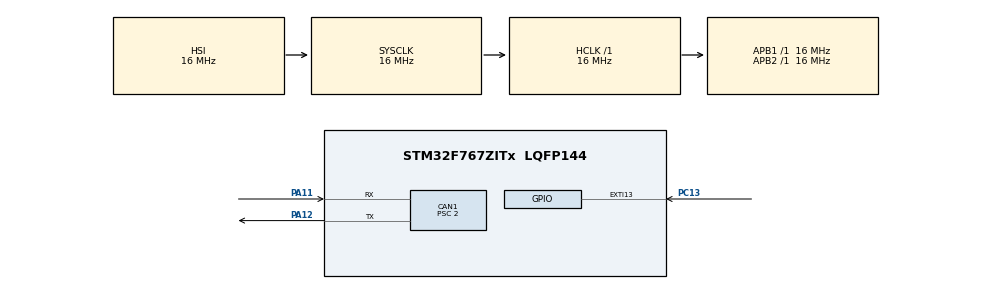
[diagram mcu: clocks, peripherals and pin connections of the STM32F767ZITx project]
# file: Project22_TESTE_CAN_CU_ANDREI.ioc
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CAN1.BS1=CAN_BS1_13TQ
CAN1.BS2=CAN_BS2_2TQ
CAN1.CalculateTimeQuantum=125.0
CAN1.Prescaler=2
Mcu.Family=STM32F7
Mcu.Name=STM32F767ZITx
Mcu.Package=LQFP144
NVIC.CAN1_RX0_IRQn=true\:0\:0\:false\:false\:true\:true\:true
NVIC.EXTI15_10_IRQn=true\:0\:0\:false\:false\:true\:true\:true
NVIC.PriorityGroup=NVIC_PRIORITYGROUP_4
PA11.Mode=Master
PA11.Signal=CAN1_RX
PA12.Mode=Master
PA12.Signal=CAN1_TX
PC13.Signal=GPXTI13
ProjectManager.HeapSize=0x200
ProjectManager.StackSize=0x400
ProjectManager.TargetToolchain=EWARM V8
RCC.48MHZClocksFreq_Value=24000000
RCC.AHBFreq_Value=16000000
RCC.APB1Freq_Value=16000000
RCC.APB1TimFreq_Value=16000000
RCC.APB2Freq_Value=16000000
RCC.APB2TimFreq_Value=16000000
RCC.CortexFreq_Value=16000000
RCC.HCLKFreq_Value=16000000
RCC.HSE_VALUE=16000000
RCC.HSI_VALUE=16000000
RCC.LSE_VALUE=32768
RCC.PLLMUL=RCC_PLL_MUL9
RCC.PRESCALERUSB=RCC_USBCLKSOURCE_PLL_DIV1_5
RCC.SYSCLKFreq_VALUE=16000000
RCC.SYSCLKSourceVirtual=RCC_SYSCLKSOURCE_PLLCLK
RCC.USBFreq_Value=96000000
RCC.VCOOutputFreq_Value=192000000
board=NUCLEO-F767ZI

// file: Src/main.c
/* USER CODE BEGIN Header */
/**
  ******************************************************************************
  * @file           : main.c
  * @brief          : Main program body
  ******************************************************************************
  * @attention
  *
  * <h2><center>&copy; Copyright (c) 2021 STMicroelectronics.
  * All rights reserved.</center></h2>
  *
  * This software component is licensed by ST under BSD 3-Clause license,
  * the "License"; You may not use this file except in compliance with the
  * License. You may obtain a copy of the License at:
  *                        opensource.org/licenses/BSD-3-Clause
  *
  ******************************************************************************
  */
/* USER CODE END Header */

#include "main.h"

CAN_HandleTypeDef hcan1;

/* USER CODE BEGIN PV */
CanTxMsgTypeDef txMsg;
CanRxMsgTypeDef rxMsg;

uint8_t msg;
uint8_t msg2;
CAN_FilterConfTypeDef sFConfig;
/* USER CODE END PV */

void SystemClock_Config(void);
static void MX_GPIO_Init(void);
static void MX_CAN1_Init(void);

int main(void)
{

  /* MCU Configuration--------------------------------------------------------*/

  /* Reset of all peripherals, Initializes the Flash interface and the Systick. */
  HAL_Init();

  /* Configure the system clock */
  SystemClock_Config();

  /* Initialize all configured peripherals */
  MX_GPIO_Init();
  MX_CAN1_Init();
  /* USER CODE BEGIN 2 */
    txMsg.StdId = 0x101;
    txMsg.ExtId = 0x01;
    txMsg.IDE = CAN_ID_STD;
    txMsg.RTR = CAN_RTR_DATA;
    txMsg.DLC = 8;

    hcan1.pTxMsg = &txMsg;
    hcan1.pRxMsg = &rxMsg;

     sFConfig.FilterNumber = 0; // [0..13]
     sFConfig.FilterMode = CAN_FILTERMODE_IDMASK;
     sFConfig.FilterScale = CAN_FILTERSCALE_32BIT;
     sFConfig.FilterIdHigh = 0; //COMP
     sFConfig.FilterIdLow = 0;
     sFConfig.FilterMaskIdHigh = 0; //MASK
     sFConfig.FilterMaskIdLow = 0;
     sFConfig.FilterFIFOAssignment = 0;
     sFConfig.FilterActivation = ENABLE;
     sFConfig.BankNumber = 14;
     HAL_CAN_ConfigFilter(&hcan1, &sFConfig);
     hcan1.pTxMsg->Data[0]=2;
     hcan1.pTxMsg->Data[1]=5;
     hcan1.pTxMsg->Data[2]=3;
     hcan1.pTxMsg->Data[3]=2;
     hcan1.pTxMsg->Data[4]=5;

  /* USER CODE END 2 */

  /* Infinite loop */
  while (1)
  {

  }
}

void SystemClock_Config(void)
{
  RCC_OscInitTypeDef RCC_OscInitStruct = {0};
  RCC_ClkInitTypeDef RCC_ClkInitStruct = {0};

  /** Configure the main internal regulator output voltage
  */
  __HAL_RCC_PWR_CLK_ENABLE();
  __HAL_PWR_VOLTAGESCALING_CONFIG(PWR_REGULATOR_VOLTAGE_SCALE3);
  /** Initializes the CPU, AHB and APB busses clocks
  */
  RCC_OscInitStruct.OscillatorType = RCC_OSCILLATORTYPE_HSI;
  RCC_OscInitStruct.HSIState = RCC_HSI_ON;
  RCC_OscInitStruct.HSICalibrationValue = RCC_HSICALIBRATION_DEFAULT;
  RCC_OscInitStruct.PLL.PLLState = RCC_PLL_NONE;
  if (HAL_RCC_OscConfig(&RCC_OscInitStruct) != HAL_OK)
  {
    Error_Handler();
  }
  /** Initializes the CPU, AHB and APB busses clocks
  */
  RCC_ClkInitStruct.ClockType = RCC_CLOCKTYPE_HCLK|RCC_CLOCKTYPE_SYSCLK
                              |RCC_CLOCKTYPE_PCLK1|RCC_CLOCKTYPE_PCLK2;
  RCC_ClkInitStruct.SYSCLKSource = RCC_SYSCLKSOURCE_HSI;
  RCC_ClkInitStruct.AHBCLKDivider = RCC_SYSCLK_DIV1;
  RCC_ClkInitStruct.APB1CLKDivider = RCC_HCLK_DIV1;
  RCC_ClkInitStruct.APB2CLKDivider = RCC_HCLK_DIV1;

  if (HAL_RCC_ClockConfig(&RCC_ClkInitStruct, FLASH_LATENCY_0) != HAL_OK)
  {
    Error_Handler();
  }
}

static void MX_CAN1_Init(void)
{

  hcan1.Instance = CAN1;
  hcan1.Init.Prescaler = 2;
  hcan1.Init.Mode = CAN_MODE_NORMAL;
  hcan1.Init.SJW = CAN_SJW_1TQ;
  hcan1.Init.BS1 = CAN_BS1_13TQ;
  hcan1.Init.BS2 = CAN_BS2_2TQ;
  hcan1.Init.TTCM = DISABLE;
  hcan1.Init.ABOM = DISABLE;
  hcan1.Init.AWUM = DISABLE;
  hcan1.Init.NART = DISABLE;
  hcan1.Init.RFLM = DISABLE;
  hcan1.Init.TXFP = DISABLE;
  if (HAL_CAN_Init(&hcan1) != HAL_OK)
  {
    Error_Handler();
  }

}

static void MX_GPIO_Init(void)
{
  GPIO_InitTypeDef GPIO_InitStruct = {0};

  /* GPIO Ports Clock Enable */
  __HAL_RCC_GPIOC_CLK_ENABLE();
  __HAL_RCC_GPIOA_CLK_ENABLE();

  /*Configure GPIO pin : PC13 */
  GPIO_InitStruct.Pin = GPIO_PIN_13;
  GPIO_InitStruct.Mode = GPIO_MODE_IT_RISING;
  GPIO_InitStruct.Pull = GPIO_NOPULL;
  HAL_GPIO_Init(GPIOC, &GPIO_InitStruct);

  /* EXTI interrupt init*/
  HAL_NVIC_SetPriority(EXTI15_10_IRQn, 0, 0);
  HAL_NVIC_EnableIRQ(EXTI15_10_IRQn);

}

void Error_Handler(void)
{
}

/************************ (C) COPYRIGHT STMicroelectronics *****END OF FILE****/
